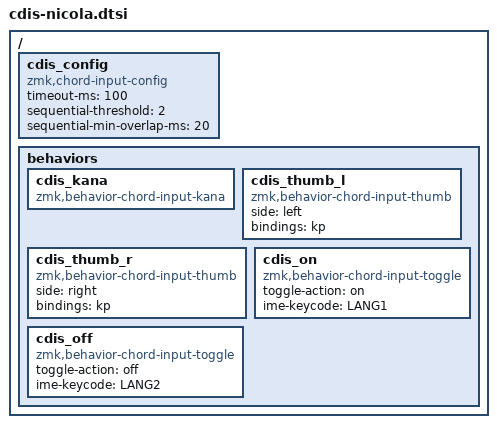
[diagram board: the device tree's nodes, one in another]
/*
 * Copyright (c) 2026 The ZMK Contributors
 *
 * SPDX-License-Identifier: MIT
 *
 * zmk-chord-input-system: Pre-built NICOLA behavior instances.
 * Include this file from your keymap to get all NICOLA behaviors.
 *
 * Usage:
 *   #include <behaviors/cdis-nicola.dtsi>
 *   #define LY_CDIS 1
 *   ...
 *   chord_input_layer {
 *       bindings = <&cdis_u &cdis_si ... &cdis_thumb_l SPACE &cdis_thumb_r SPACE>;
 *   };
 */

#include <dt-bindings/zmk/keys.h>
#include <zmk-chordis/keys.h>
#include <zmk-chordis/chord-input-map.h>
#include <zmk-chordis/helpers.h>

/ {
    cdis_config: cdis_config {
        compatible = "zmk,chord-input-config";
        timeout-ms = <100>;
        sequential-threshold = <2>;
        sequential-min-overlap-ms = <20>;
        /*
         * Auto-off: deactivate NICOLA when specific mod+key combos are pressed.
         * Each entry is a (modifier_mask, keycode) pair.
         * Uncomment and adjust for your workflow (e.g. Emacs C-x, C-s, M-x):
         *
         * auto-off-keys = <(MOD_LCTL|MOD_RCTL) X
         *                  (MOD_LCTL|MOD_RCTL) S
         *                  (MOD_LALT|MOD_RALT) X>;
         */
    };

    behaviors {
        /*
         * Character keys (30 instances)
         * CHORD_INPUT_BEHAVIOR(name, unshifted, left_shifted, right_shifted)
         *
         * Layout reference: NICOLA spec figures 1-2, with 2018.11 errata applied.
         * Left column = same-side shift, right column = cross shift (and vice versa).
         */

        /* === D段 (top row) === */
        /* D01 */ CHORD_INPUT_BEHAVIOR(kuten,  KANA_KUTEN,    KANA_SMALL_A,  KANA_SMALL_A)
        /* D02 */ CHORD_INPUT_BEHAVIOR(ka,     KANA_KA,       KANA_E,        KANA_GA)
        /* D03 */ CHORD_INPUT_BEHAVIOR(ta,     KANA_TA,       KANA_RI,       KANA_DA)
        /* D04 */ CHORD_INPUT_BEHAVIOR(ko,     KANA_KO,       KANA_SMALL_YA, KANA_GO)
        /* D05 */ CHORD_INPUT_BEHAVIOR(sa,     KANA_SA,       KANA_RE,       KANA_ZA)
        /* D06 */ CHORD_INPUT_BEHAVIOR(ra,     KANA_RA,       KANA_PA,       KANA_YO)
        /* D07 */ CHORD_INPUT_BEHAVIOR(ti,     KANA_TI,       KANA_DI,       KANA_NI)
        /* D08 */ CHORD_INPUT_BEHAVIOR(ku,     KANA_KU,       KANA_GU,       KANA_RU)
        /* D09 */ CHORD_INPUT_BEHAVIOR(tu,     KANA_TU,       KANA_DU,       KANA_MA)
        /* D10 */ CHORD_INPUT_BEHAVIOR(comma,  KANA_COMMA,    KANA_PI,       KANA_SMALL_E)
        /* D11 */ CHORD_INPUT_BEHAVIOR(touten, KANA_TOUTEN,   KANA_NONE,     KANA_NONE)

        /* === C段 (home row) === */
        /* C01 */ CHORD_INPUT_BEHAVIOR(u,      KANA_U,        KANA_WO,       KANA_VU)
        /* C02 */ CHORD_INPUT_BEHAVIOR(si,     KANA_SI,       KANA_A,        KANA_ZI)
        /* C03 */ CHORD_INPUT_BEHAVIOR(te,     KANA_TE,       KANA_NA,       KANA_DE)
        /* C04 */ CHORD_INPUT_BEHAVIOR(ke,     KANA_KE,       KANA_SMALL_YU, KANA_GE)
        /* C05 */ CHORD_INPUT_BEHAVIOR(se,     KANA_SE,       KANA_MO,       KANA_ZE)
        /* C06 */ CHORD_INPUT_BEHAVIOR(ha,     KANA_HA,       KANA_BA,       KANA_MI)
        /* C07 */ CHORD_INPUT_BEHAVIOR(to,     KANA_TO,       KANA_DO,       KANA_O)
        /* C08 */ CHORD_INPUT_BEHAVIOR(ki,     KANA_KI,       KANA_GI,       KANA_NO)
        /* C09 */ CHORD_INPUT_BEHAVIOR(i,      KANA_I,        KANA_PO,       KANA_SMALL_YO)
        /* C10 */ CHORD_INPUT_BEHAVIOR(nn,     KANA_NN,       KANA_NONE,     KANA_SMALL_TU)

        /* === B段 (bottom row) === */
        /* B01 */ CHORD_INPUT_BEHAVIOR(period, KANA_PERIOD,   KANA_SMALL_U,  KANA_SMALL_U)
        /* B02 */ CHORD_INPUT_BEHAVIOR(hi,     KANA_HI,       KANA_CHOUON,   KANA_BI)
        /* B03 */ CHORD_INPUT_BEHAVIOR(su,     KANA_SU,       KANA_RO,       KANA_ZU)
        /* B04 */ CHORD_INPUT_BEHAVIOR(hu,     KANA_HU,       KANA_YA,       KANA_BU)
        /* B05 */ CHORD_INPUT_BEHAVIOR(he,     KANA_HE,       KANA_SMALL_I,  KANA_BE)
        /* B06 */ CHORD_INPUT_BEHAVIOR(me,     KANA_ME,       KANA_PU,       KANA_NU)
        /* B07 */ CHORD_INPUT_BEHAVIOR(so,     KANA_SO,       KANA_ZO,       KANA_YU)
        /* B08 */ CHORD_INPUT_BEHAVIOR(ne,     KANA_NE,       KANA_PE,       KANA_MU)
        /* B09 */ CHORD_INPUT_BEHAVIOR(ho,     KANA_HO,       KANA_BO,       KANA_WA)
        /* B10 */ CHORD_INPUT_BEHAVIOR(nakaguro, KANA_NAKAGURO, KANA_NONE,   KANA_SMALL_O)

        /* === Kana output behavior (for thumb tap etc.) === */
        cdis_kana: cdis_kana {
            compatible = "zmk,behavior-chord-input-kana";
            #binding-cells = <1>;
        };

        /* === Thumb keys (2 instances) === */
        cdis_thumb_l: cdis_thumb_l {
            compatible = "zmk,behavior-chord-input-thumb";
            #binding-cells = <1>;
            side = "left";
            bindings = <&kp>;
        };
        cdis_thumb_r: cdis_thumb_r {
            compatible = "zmk,behavior-chord-input-thumb";
            #binding-cells = <1>;
            side = "right";
            bindings = <&kp>;
        };

        /*
         * Additional grid-based shift keys (for yōon etc.).
         * Place these on character key positions in the keymap.
         * Tap = kana output (via tap binding), simultaneous = extra shift.
         *
         * Example: cdis_shift2 for yōon shift:
         *   cdis_shift2: cdis_shift2 {
         *       compatible = "zmk,behavior-chord-input-thumb";
         *       #binding-cells = <1>;
         *       side = "shift2";
         *       bindings = <&cdis_kana>;
         *   };
         * In keymap: &cdis_shift2 KANA_TE  (tap = て, simultaneous = shift2)
         *
         * Character keys using this shift need CHORD_INPUT_BEHAVIOR5:
         *   CHORD_INPUT_BEHAVIOR5(ka, KANA_KA, KANA_GA, KANA_E, KANA_KYA, KANA_NONE)
         *                       unshifted  shift0   shift1  shift2    shift3
         */

        /* === Mode toggle (2 instances, idempotent) === */
        cdis_on: cdis_on {
            compatible = "zmk,behavior-chord-input-toggle";
            #binding-cells = <1>;
            toggle-action = "on";
            ime-keycode = <LANG1>;
        };
        cdis_off: cdis_off {
            compatible = "zmk,behavior-chord-input-toggle";
            #binding-cells = <1>;
            toggle-action = "off";
            ime-keycode = <LANG2>;
        };
    };
};
